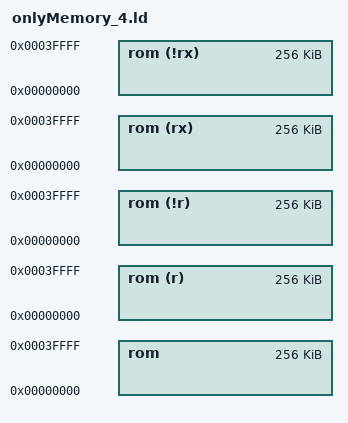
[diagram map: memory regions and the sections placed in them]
MEMORY 
{
    rom   : ORIGIN = 0, LENGTH = 256K
    rom (r)  : ORIGIN = 0, LENGTH = 256K
    rom (!r)  : ORIGIN = 0, LENGTH = 256K
    rom (rx)  : ORIGIN = 0, LENGTH = 256K
    rom (!rx)  : ORIGIN = 0, LENGTH = 256K
}
